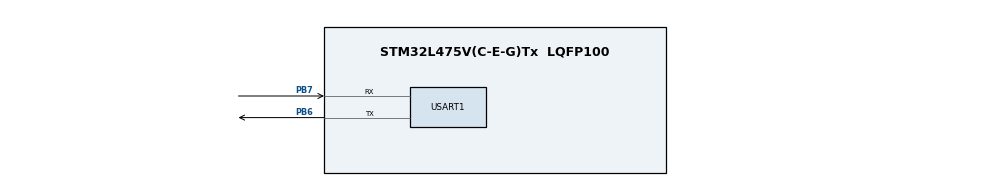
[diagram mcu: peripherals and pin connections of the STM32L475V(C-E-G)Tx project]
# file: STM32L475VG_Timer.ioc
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Mcu.Family=STM32L4
Mcu.Name=STM32L475V(C-E-G)Tx
Mcu.Package=LQFP100
NVIC.PriorityGroup=NVIC_PRIORITYGROUP_4
PB6.Mode=Asynchronous
PB6.Signal=USART1_TX
PB7.Mode=Asynchronous
PB7.Signal=USART1_RX
ProjectManager.HeapSize=0x200
ProjectManager.StackSize=0x400
ProjectManager.TargetToolchain=STM32CubeIDE
RCC.HSE_VALUE=8000000
RCC.HSI_VALUE=16000000
RCC.LSE_VALUE=32768
RCC.MSI_VALUE=4000000
RCC.VCOOutputFreq_Value=32000000
TIM16.Period=65536 -1
TIM16.Prescaler=8000 - 1
USART1.VirtualMode-Asynchronous=VM_ASYNC
VP_TIM16_VS_ClockSourceINT.Mode=Enable_Timer
board=custom

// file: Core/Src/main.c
/* USER CODE BEGIN Header */
/**
  ******************************************************************************
  * @file           : main.c
  * @brief          : Main program body
  ******************************************************************************
  * @attention
  *
  * <h2><center>&copy; Copyright (c) 2020 STMicroelectronics.
  * All rights reserved.</center></h2>
  *
  * This software component is licensed by ST under BSD 3-Clause license,
  * the "License"; You may not use this file except in compliance with the
  * License. You may obtain a copy of the License at:
  *                        opensource.org/licenses/BSD-3-Clause
  *
  ******************************************************************************
  */
/* USER CODE END Header */
#include "main.h"

/* USER CODE BEGIN Includes */
#include <stdio.h>
/* USER CODE END Includes */

TIM_HandleTypeDef htim16;

UART_HandleTypeDef huart1;

void SystemClock_Config(void);
static void MX_GPIO_Init(void);
static void MX_TIM16_Init(void);
static void MX_USART1_UART_Init(void);

int main(void)
{
  /* USER CODE BEGIN 1 */
	char uart_buf[50];
	int uart_buf_len;
	uint16_t timer_val;
  /* USER CODE END 1 */

  /* MCU Configuration--------------------------------------------------------*/

  /* Reset of all peripherals, Initializes the Flash interface and the Systick. */
  HAL_Init();

  /* Configure the system clock */
  SystemClock_Config();

  /* Initialize all configured peripherals */
  MX_GPIO_Init();
  MX_TIM16_Init();
  MX_USART1_UART_Init();
  /* USER CODE BEGIN 2 */
  //Say Something
  uart_buf_len = sprintf(uart_buf, "Timer test\r\n");
  HAL_UART_Transmit(&huart1, (uint8_t *)uart_buf,uart_buf_len, 100 );

  //Start timer
  HAL_TIM_Base_Start(&htim16);
  /* USER CODE END 2 */

  /* Infinite loop */
  /* USER CODE BEGIN WHILE */
  while (1)
  {
	  //Get current time (microseconds)
	  timer_val = __HAL_TIM_GET_COUNTER(&htim16);

	  //wait  for 50 ms
	  HAL_Delay(50);

	  //Get time elapsed
	  timer_val = __HAL_TIM_GET_COUNTER(&htim16) - timer_val;

	  //Show elapsed time
	  uart_buf_len = sprintf(uart_buf, "%u us \r\n", timer_val);
	  HAL_UART_Transmit(&huart1, (uint8_t *)uart_buf,uart_buf_len, 100 );

	  //Wait again so we don't flood the serial terminal
	  HAL_Delay(1000);
    /* USER CODE END WHILE */

  }
}

void SystemClock_Config(void)
{
  RCC_OscInitTypeDef RCC_OscInitStruct = {0};
  RCC_ClkInitTypeDef RCC_ClkInitStruct = {0};
  RCC_PeriphCLKInitTypeDef PeriphClkInit = {0};

  /** Initializes the RCC Oscillators according to the specified parameters
  * in the RCC_OscInitTypeDef structure.
  */
  RCC_OscInitStruct.OscillatorType = RCC_OSCILLATORTYPE_MSI;
  RCC_OscInitStruct.MSIState = RCC_MSI_ON;
  RCC_OscInitStruct.MSICalibrationValue = 0;
  RCC_OscInitStruct.MSIClockRange = RCC_MSIRANGE_6;
  RCC_OscInitStruct.PLL.PLLState = RCC_PLL_NONE;
  if (HAL_RCC_OscConfig(&RCC_OscInitStruct) != HAL_OK)
  {
    Error_Handler();
  }
  /** Initializes the CPU, AHB and APB buses clocks
  */
  RCC_ClkInitStruct.ClockType = RCC_CLOCKTYPE_HCLK|RCC_CLOCKTYPE_SYSCLK
                              |RCC_CLOCKTYPE_PCLK1|RCC_CLOCKTYPE_PCLK2;
  RCC_ClkInitStruct.SYSCLKSource = RCC_SYSCLKSOURCE_MSI;
  RCC_ClkInitStruct.AHBCLKDivider = RCC_SYSCLK_DIV1;
  RCC_ClkInitStruct.APB1CLKDivider = RCC_HCLK_DIV1;
  RCC_ClkInitStruct.APB2CLKDivider = RCC_HCLK_DIV1;

  if (HAL_RCC_ClockConfig(&RCC_ClkInitStruct, FLASH_LATENCY_0) != HAL_OK)
  {
    Error_Handler();
  }
  PeriphClkInit.PeriphClockSelection = RCC_PERIPHCLK_USART1;
  PeriphClkInit.Usart1ClockSelection = RCC_USART1CLKSOURCE_PCLK2;
  if (HAL_RCCEx_PeriphCLKConfig(&PeriphClkInit) != HAL_OK)
  {
    Error_Handler();
  }
  /** Configure the main internal regulator output voltage
  */
  if (HAL_PWREx_ControlVoltageScaling(PWR_REGULATOR_VOLTAGE_SCALE1) != HAL_OK)
  {
    Error_Handler();
  }
}

static void MX_TIM16_Init(void)
{

  htim16.Instance = TIM16;
  htim16.Init.Prescaler = 8000 - 1;
  htim16.Init.CounterMode = TIM_COUNTERMODE_UP;
  htim16.Init.Period = 65536 -1;
  htim16.Init.ClockDivision = TIM_CLOCKDIVISION_DIV1;
  htim16.Init.RepetitionCounter = 0;
  htim16.Init.AutoReloadPreload = TIM_AUTORELOAD_PRELOAD_DISABLE;
  if (HAL_TIM_Base_Init(&htim16) != HAL_OK)
  {
    Error_Handler();
  }

}

static void MX_USART1_UART_Init(void)
{

  huart1.Instance = USART1;
  huart1.Init.BaudRate = 115200;
  huart1.Init.WordLength = UART_WORDLENGTH_8B;
  huart1.Init.StopBits = UART_STOPBITS_1;
  huart1.Init.Parity = UART_PARITY_NONE;
  huart1.Init.Mode = UART_MODE_TX_RX;
  huart1.Init.HwFlowCtl = UART_HWCONTROL_NONE;
  huart1.Init.OverSampling = UART_OVERSAMPLING_16;
  huart1.Init.OneBitSampling = UART_ONE_BIT_SAMPLE_DISABLE;
  huart1.AdvancedInit.AdvFeatureInit = UART_ADVFEATURE_NO_INIT;
  if (HAL_UART_Init(&huart1) != HAL_OK)
  {
    Error_Handler();
  }

}

static void MX_GPIO_Init(void)
{

  /* GPIO Ports Clock Enable */
  __HAL_RCC_GPIOB_CLK_ENABLE();

}

void Error_Handler(void)
{
}

/************************ (C) COPYRIGHT STMicroelectronics *****END OF FILE****/
